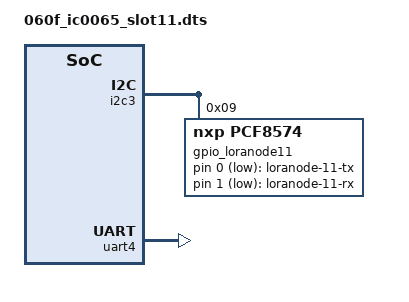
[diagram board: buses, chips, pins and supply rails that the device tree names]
/dts-v1/;


/plugin/;

/ {
	fragment@0 {
		target = <&i2c3>;
		__overlay__ {
			#address-cells = <1>;
			#size-cells = <0>;
			gpio_loranode11: pca9501@9 {
				compatible = "nxp,pcf8574";
				gpio-controller;
				#gpio-cells = <2>;
				reg = <9>;
				lines-initial-states = <0x10>;
				gpio-line-names = "SLOT11_LORANODE_LED1",
				"SLOT11_LORANODE_LED2",
				"SLOT11_LORANODE_CTS",
				"SLOT11_LORANODE_RTS",
				"SLOT11_LORANODE_RESET",
				"SLOT11_LORANODE_BOOT",
				"",
				"";
			};
		};
	};

	fragment@3 {
		
		target = <&uart4>;
		__overlay__ {
			status = "okay";
		};

	};

	fragment@4 {
		target-path = "/";
		__overlay__ {
			loraleds {
				compatible = "gpio-leds";
				lora-led@0 {
					label = "loranode-11-tx";
					gpios = <&gpio_loranode11 0 1>;
					default-state = "off";
					linux,default-trigger = "none";
				};
				lora-led@1 {
					label = "loranode-11-rx";
					gpios = <&gpio_loranode11 1 1>;
					default-state = "off";
					linux,default-trigger = "none";
				};
			};
		};
	};
};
